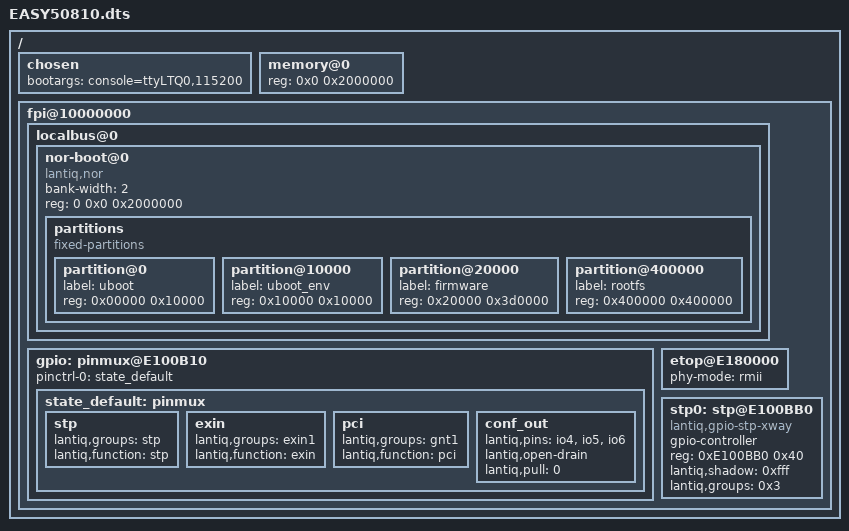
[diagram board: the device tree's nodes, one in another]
/dts-v1/;

#include "ar9.dtsi"

/ {
	chosen {
		bootargs = "console=ttyLTQ0,115200";
	};

	memory@0 {
		reg = <0x0 0x2000000>;
	};

	fpi@10000000 {
		localbus@0 {
			nor-boot@0 {
				compatible = "lantiq,nor";
				bank-width = <2>;
				reg = <0 0x0 0x2000000>;
				#address-cells = <1>;
				#size-cells = <1>;

				partitions {
					compatible = "fixed-partitions";
					#address-cells = <1>;
					#size-cells = <1>;

					partition@0 {
						label = "uboot";
						reg = <0x00000 0x10000>; /* 64 KB */
					};

					partition@10000 {
						label = "uboot_env";
						reg = <0x10000 0x10000>; /* 64 KB */
					};

					partition@20000 {
						label = "firmware";
						reg = <0x20000 0x3d0000>;
					};

					partition@400000 {
						label = "rootfs";
						reg = <0x400000 0x400000>;
					};
				};
			};
		};

		gpio: pinmux@E100B10 {
			pinctrl-names = "default";
			pinctrl-0 = <&state_default>;

			state_default: pinmux {
				stp {
					lantiq,groups = "stp";
					lantiq,function = "stp";
				};
				exin {
					lantiq,groups = "exin1";
					lantiq,function = "exin";
				};
				pci {
					lantiq,groups = "gnt1";
					lantiq,function = "pci";
				};
				conf_out {
					lantiq,pins = "io4", "io5", "io6"; /* stp */
					lantiq,open-drain;
					lantiq,pull = <0>;
				};
			};
		};

		etop@E180000 {
			phy-mode = "rmii";
		};

		stp0: stp@E100BB0 {
			#gpio-cells = <2>;
			compatible = "lantiq,gpio-stp-xway";
			gpio-controller;
			reg = <0xE100BB0 0x40>;

			lantiq,shadow = <0xfff>;
			lantiq,groups = <0x3>;
		};
	};
};
